AUTOSAR XML (schema 00050)
package /FCADT/ComponentTypes
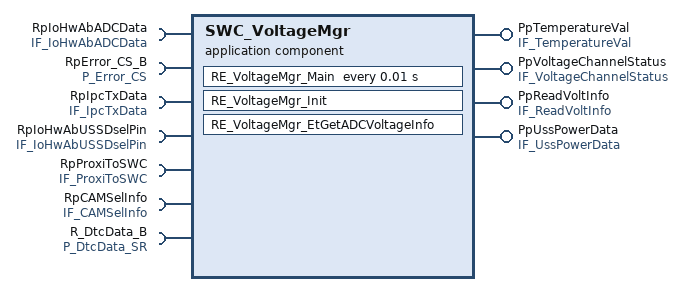
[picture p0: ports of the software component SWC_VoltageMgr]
  application sw component type SWC_VoltageMgr
    provide port PpTemperatureVal: nonqueued-sender-com-spec{data-element=GetTemperatureVal, init-value=constant-reference=init_GetTemperatureVal}, provided-interface=IF_TemperatureVal
    require port RpIoHwAbADCData: client-com-spec=GetRawValues, required-interface=IF_IoHwAbADCData
    provide port PpVoltageChannelStatus: nonqueued-sender-com-spec{data-element=BatteryVoltageStatus, init-value=constant-reference=init_BatteryVoltageStatus}, provided-interface=IF_VoltageChannelStatus
    provide port PpReadVoltInfo: server-com-spec{operation=GetVoltageInfo, queue-length=1}, provided-interface=IF_ReadVoltInfo
    4 x require port:
      RpError_CS_B: client-com-spec=ReportErrorStatus1_0_B, required-interface=P_Error_CS
      RpIpcTxData: client-com-spec=IPC_Write_v, required-interface=IF_IpcTxData
      RpIoHwAbUSSDselPin: client-com-spec=GetUSSDselPinStatus, required-interface=IF_IoHwAbUSSDselPin
      RpProxiToSWC: required-interface=IF_ProxiToSWC
        required-com-specs:
          data-element=TyreSz_u16, filter=data-filter-type=ALWAYS
          data-element=SurroundViewCam_u8, filter=data-filter-type=ALWAYS
          data-element=Fullautomaticparking, filter=data-filter-type=ALWAYS
          data-element=PRX_CanNod27_b
          data-element=Parkwithstop_u8
          data-element=Trailerhitchassist_u8
          data-element=PAMConfig_u8
          data-element=Pamtuningset
    provide port PpUssPowerData: nonqueued-sender-com-spec{data-element=UssPower, init-value=fields=[v_USS_PWR_A_MON_f32:0, v_USS_PWR_B_MON_f32:0, v_USS_PWR_C_MON_f32:0, v_USS_PWR_IS1_MON_MON_f32:[0, 0], v_USS_PWR_IS2_MON_MON_f32:0]}, provided-interface=IF_UssPowerData
    require port RpCAMSelInfo: nonqueued-receiver-com-spec{data-element=CAM_select_info_t, filter=data-filter-type=ALWAYS}, required-interface=IF_CAMSelInfo
    require port R_DtcData_B: required-interface=P_DtcData_SR
      required-com-specs:
        data-element=Data_DtcAddData_B, filter=data-filter-type=ALWAYS
        data-element=Data_DtcStatus_B, filter=data-filter-type=ALWAYS
    behavior SWC_VoltageMgr_InternalBehavior: handle-termination-and-restart=NO-SUPPORT
      init event InitEvent: start-on-event=RE_VoltageMgr_Init
      timing event TMT_RE_VoltageMgr_Main: start-on-event=RE_VoltageMgr_Main, period=0.01
      operation invoked event OIT_RE_VoltageMgr_EtGetADCVoltageInfo_PpReadVoltInfo_GetVoltageInfo: start-on-event=RE_VoltageMgr_EtGetADCVoltageInfo, operation=PpReadVoltInfo.GetVoltageInfo
      port-api-options:
        enable-take-address=false, error-handling=NO-TRANSFORMER-ERROR-HANDLING, indirect-api=false, port=PpTemperatureVal
        enable-take-address=false, error-handling=NO-TRANSFORMER-ERROR-HANDLING, indirect-api=false, port=RpIoHwAbADCData
        enable-take-address=false, error-handling=NO-TRANSFORMER-ERROR-HANDLING, indirect-api=false, port=PpVoltageChannelStatus
        enable-take-address=false, error-handling=NO-TRANSFORMER-ERROR-HANDLING, indirect-api=false, port=PpReadVoltInfo
      runnable RE_VoltageMgr_Init
      runnable RE_VoltageMgr_Main
        data-receive-point-by-arguments:
          4 x access:
            REC_RpProxiToSWC_SurroundViewCam_u8: accessed-variable=RpProxiToSWC.SurroundViewCam_u8
            REC_RpCAMSelInfo_CAM_select_info_t: accessed-variable=RpCAMSelInfo.CAM_select_info_t
            REC_R_DtcData_B_Data_DtcAddData_B: accessed-variable=R_DtcData_B.Data_DtcAddData_B
            REC_R_DtcData_B_Data_DtcStatus_B: accessed-variable=R_DtcData_B.Data_DtcStatus_B
        data-send-points:
          access SEND_PpTemperatureVal_GetTemperatureVal: accessed-variable=PpTemperatureVal.GetTemperatureVal
          access SEND_PpUssPowerData_UssPower: accessed-variable=PpUssPowerData.UssPower
        4 x sync call:
          SC_RpIoHwAbADCData_GetRawValues: operation=RpIoHwAbADCData.GetRawValues, timeout=0
          SC_RpError_CS_B_ReportErrorStatus1_0_B: operation=RpError_CS_B.ReportErrorStatus1_0_B
          SC_RpIpcTxData_IPC_Write_v: operation=RpIpcTxData.IPC_Write_v
          SC_RpIoHwAbUSSDselPin_GetUSSDselPinStatus: operation=RpIoHwAbUSSDselPin.GetUSSDselPinStatus
      runnable RE_VoltageMgr_EtGetADCVoltageInfo: can-be-invoked-concurrently=true
        data-send-points:
          access SEND_PpVoltageChannelStatus_BatteryVoltageStatus: accessed-variable=PpVoltageChannelStatus.BatteryVoltageStatus
  swc implementation SWC_VoltageMgr_Implementation: programming-language=C, vendor-id=0, behavior=SWC_VoltageMgr_InternalBehavior
    code-descriptors:
      code Default: artifact-descriptors=autosar-engineering-object=category=SWSRC
